# AE350_4GB register map
Vendor: Andes Technology; Series: AE350; File version: 1.3.0
Registers are 32-bit, read-write, reset 0x0 unless marked. A register's access mark holds for its fields unless they carry their own. Offsets are from the block's base; [hi:lo] are bit positions; {n}, {i} and the like mark numbered series.

## UART1 — UART1 Controller Registers
Base 0xF0200000
Same registers: UART2 0xF0300000
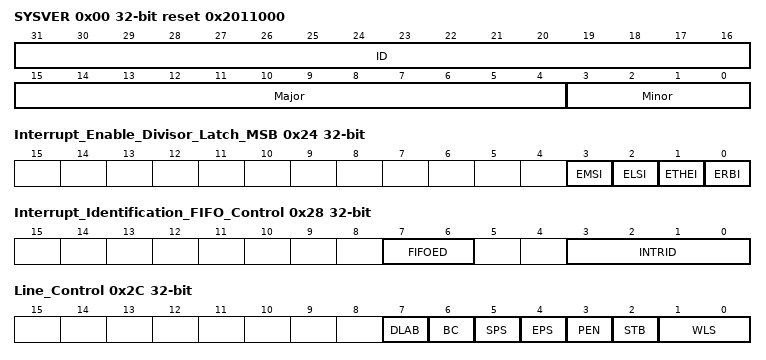
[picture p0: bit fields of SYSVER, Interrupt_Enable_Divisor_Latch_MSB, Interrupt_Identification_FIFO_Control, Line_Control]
0x00 SYSVER ro reset 0x2011000 — SYSTEM ID & Revision Register.
  [31:16] ID — ID number for ATCUART100
  [15:4] Major — Major revision number
  [3:0] Minor — Minor revision number
0x10 HWCFGR ro — Hardware Configure Register
  [1:0] FIFO_DEPTH — The depth of RXFIFO and TXFIFO
0x14 OSCR reset 0x10 — Over Sample Control register
  [4:0] OSC — Over-sample control
0x20 Receiver_Buffer_Transmitter_Holding_Divisor_Latch_LSB reset 0x1 — Receiver Buffer Register (RBR) (when DLAB = 0) / Transmitter Holding Register (THR) (when DLAB = 0) / Divisor Latch LSB (DLL) (when DLAB = 1)
  [7:0] RBR ro — Receive data read port
0x24 Interrupt_Enable_Divisor_Latch_MSB — Interrupt Enable Register (IER) (when DLAB = 0) / Divisor Latch MSB (DLM) (when DLAB = 1)
  [3] EMSI — Enable modem status interrupt
  [2] ELSI — Enable receiver line status interrupt
  [1] ETHEI — Enable transmitter holding register interrupt
  [0] ERBI — Enable received data available interrupt
0x28 Interrupt_Identification_FIFO_Control — Interrupt Identification Register (IIR) / FIFO Control Register (FCR)
  [7:6] FIFOED ro — FIFOs enabled
  [3:0] INTRID ro — Interrupt ID
0x2C Line_Control — Line Control Register (LCR)
  [7] DLAB — Divisor latch access bit
  [6] BC — Break control
  [5] SPS — Stick parity
  [4] EPS — Even parity select
  [3] PEN — Parity enable
  [2] STB — Number of STOP bits
  [1:0] WLS — Word length setting
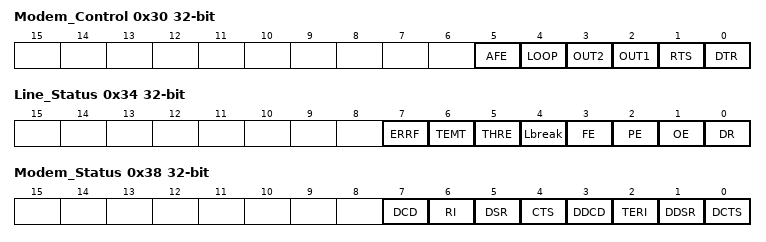
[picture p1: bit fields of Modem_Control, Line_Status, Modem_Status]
0x30 Modem_Control — Modem Control Register (MCR)
  [5] AFE — Auto flow control enable
  [4] LOOP — Enable loopback mode
  [3] OUT2 — User-defined output 2
  [2] OUT1 — User-defined output 1
  [1] RTS — Request to send
  [0] DTR — Data terminal ready
0x34 Line_Status — Line Status Register (LSR)
  [7] ERRF ro — Error in RXFIFO
  [6] TEMT ro — Transmitter empty
  [5] THRE ro — Transmitter Holding Register empty
  [4] Lbreak ro — Line break
  [3] FE ro — Framing error
  [2] PE ro — Parity error
  [1] OE ro — Overrun error
  [0] DR ro — Data ready
0x38 Modem_Status — Modem Status Register (MSR)
  [7] DCD ro — Data carrier detect
  [6] RI ro — Ring indicator
  [5] DSR ro — Data set ready
  [4] CTS ro — Clear to send
  [3] DDCD ro — Delta data carrier detect
  [2] TERI ro — Trailing edge ring indicator
  [1] DDSR ro — Delta data set ready
  [0] DCTS ro — Delta clear to send
0x3C Scratch_Register — Scratch Register (SCR)
  [7:0] SCR ro — An one-byte storage register with no UART related function

## PIT — PIT Controller Registers
Base 0xF0400000
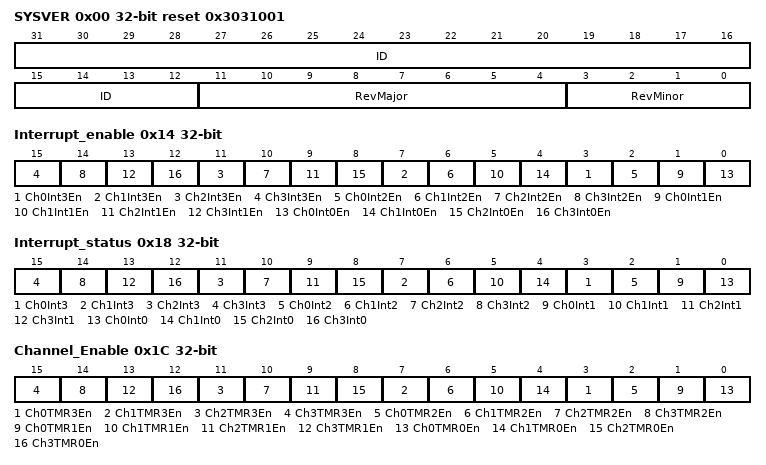
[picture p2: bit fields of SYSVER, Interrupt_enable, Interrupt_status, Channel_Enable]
0x00 SYSVER ro reset 0x3031001 — ID and Revision Register
  [31:12] ID — ID number for PIT
  [11:4] RevMajor — Major revision number
  [3:0] RevMinor — Minor revision number
0x10 Configuration ro reset not defined
  [2:0] NumCh — Number of PIT channels
0x14 Interrupt_enable
  [4n+3] Ch{n}Int3En (n=0..3) — Channel {n} Timer 3 interrupt enable
  [4n+2] Ch{n}Int2En (n=0..3) — Channel {n} Timer 2 interrupt enable
  [4n+1] Ch{n}Int1En (n=0..3) — Channel {n} Timer 1 interrupt enable
  [4n] Ch{n}Int0En (n=0..3) — Channel {n} Timer 0 interrupt enable
0x18 Interrupt_status
  [4n+3] Ch{n}Int3 (n=0..3) — Channel {n} Timer 3 interrupt status
  [4n+2] Ch{n}Int2 (n=0..3) — Channel {n} Timer 2 interrupt status
  [4n+1] Ch{n}Int1 (n=0..3) — Channel {n} Timer 1 interrupt status
  [4n] Ch{n}Int0 (n=0..3) — Channel {n} Timer 0 interrupt status
0x1C Channel_Enable
  [4n+3] Ch{n}TMR3En (n=0..3) — Channel {n} Timer 3 enable
  [4n+2] Ch{n}TMR2En (n=0..3) — Channel {n} Timer 2 enable
  [4n+1] Ch{n}TMR1En (n=0..3) — Channel {n} Timer 1 enable
  [4n] Ch{n}TMR0En (n=0..3) — Channel {n} Timer 0 enable
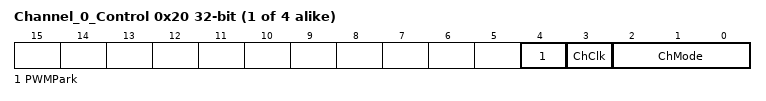
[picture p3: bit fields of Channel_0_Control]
{0x20+0x10*i} Channel_{i}_Control (i=0..3)
  [4] PWMPark — PWM park value
  [3] ChClk — Channel clock source
  [2:0] ChMode — Channel mode
{0x24+0x10*i} Channel_{i}_TMR_PWM_reload (i=0..3)
{0x28+0x10*i} Channel_{i}_TMR_PWM_counter (i=0..3)
  [31:0] Counter ro — The counter for the counting of Timer/PWM
